AUTOSAR XML (schema 00048)
package /HuaweiMDC/FunctionalSoftware/MapMviz/Execution
  executable MapMvizExecutable
    root sw component prototype MapMvizRootSwComponent: application-type=MapMvizApplicationSwComponent
package /HuaweiMDC/FunctionalSoftware/MapMviz/SwComponent
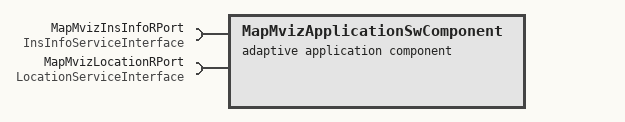
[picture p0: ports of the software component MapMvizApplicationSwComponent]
  adaptive application sw component type MapMvizApplicationSwComponent
    require port MapMvizInsInfoRPort: required-interface=InsInfoServiceInterface
    require port MapMvizLocationRPort: required-interface=LocationServiceInterface
